# STM32L4R5xx register map
File version: 1.0
Registers are 32-bit, access not given, reset 0x0 unless marked. A register's access mark holds for its fields unless they carry their own. Offsets are from the block's base; [hi:lo] are bit positions; {n}, {i} and the like mark numbered series.

## VREFBUF
Base 0x40010030
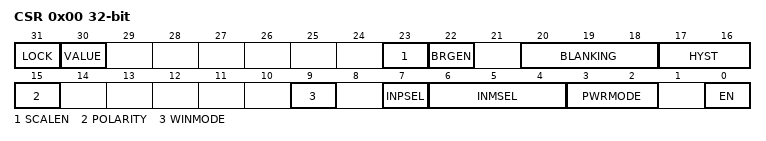
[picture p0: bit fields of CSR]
0x00 CSR
  [3] VRR, [2] VRS, [1] HIZ, [0] ENVR, [5:0] TRIM
0x04 CCR

## COMP1
Base 0x40010200
Same registers: COMP2 0x40010204, COMP12_COMMON 0x40010204
0x00 CSR
  [31] LOCK, [30] VALUE, [23] SCALEN, [22] BRGEN, [20:18] BLANKING, [17:16] HYST, [15] POLARITY, [9] WINMODE, [7] INPSEL, [6:4] INMSEL, [3:2] PWRMODE, [0] EN

## EXTI
Base 0x40010400
0x00 IMR1
  [n] IM{n} (n=0..31), [n] EM{n} (n=0..31), [n] RT{n} (n=18..22), [n] FT{n} (n=18..22), [n] SWI{n} (n=18..22), [n] PIF{n} (n=18..22), [n] RT{n} (n=0..16), [n] FT{n} (n=0..16), [n] SWI{n} (n=0..16), [n] PIF{n} (n=0..16), [8] IM40, [8] EM40, [n-32] IM{n} (n=35..38), [n-32] EM{n} (n=35..38), [n-32] RT{n} (n=35..38), [n-32] FT{n} (n=35..38), [n-32] SWI{n} (n=35..38), [n-32] PIF{n} (n=35..38), [1] IM33, [1] EM33, [0] IM32, [0] EM32
0x04 EMR1
0x08 RTSR1
0x0C FTSR1
0x10 SWIER1
0x14 PR1
0x20 IMR2
0x24 EMR2
0x28 RTSR2
0x2C FTSR2
0x30 SWIER2
0x34 PR2

## FIREWALL
Base 0x40011C00
0x00 CSSA
0x04 CSL
0x08 NVDSSA
0x0C NVDSL
0x10 VDSSA
0x14 VDSL
0x20 CR

## SAI1
Base 0x40015400
Same registers: SAI2 0x40015800
0x00 GCR
  [8n-2:8n-4] DLYM{n}R (n=1..4), [8n-6:8n-8] DLYM{n}L (n=1..4), [n+7] CKEN{n} (n=1..4), [5:4] SYNCOUT, [5:4] MICNBR, [1:0] SYNCIN, [0] PDMEN
0x04 CR1A
0x08 CR2A
0x10 FRCRA
0x1C SLOTRA
0x24 CR1B
0x28 CR2B
0x2C IMRA
0x30 FRCRB
0x3C SLOTRB
0x40 SRA
0x44 PDMCR
0x48 PDMDLY
0x4C IMRB
0x58 CLRFRA
0x60 SRB
0x74 DRA
0x78 CLRFRB
0x94 DRB

## DMA1
Base 0x40020000
Same registers: DMA2 0x40020400
0x00 ISR
  [4n-1] TEIF{n} (n=1..7), [4n-1] CTEIF{n} (n=1..7), [4n-2] HTIF{n} (n=1..7), [4n-2] CHTIF{n} (n=1..7), [4n-3] TCIF{n} (n=1..7), [4n-3] CTCIF{n} (n=1..7), [4n-4] GIF{n} (n=1..7), [4n-4] CGIF{n} (n=1..7), [14] MEM2MEM, [14] MEM2MEM, [14] MEM2MEM, [14] MEM2MEM, [14] MEM2MEM, [14] MEM2MEM, [14] MEM2MEM, [14] MEM2MEM, [14] MEM2MEM, [14] MEM2MEM, [14] MEM2MEM, [14] MEM2MEM, [14] MEM2MEM, [14] MEM2MEM, [13:12] PL, [13:12] PL, [13:12] PL, [13:12] PL, [13:12] PL, [13:12] PL, [13:12] PL, [13:12] PL, [13:12] PL, [13:12] PL, [13:12] PL, [13:12] PL, [13:12] PL, [13:12] PL, [11:10] MSIZE, [11:10] MSIZE, [11:10] MSIZE, [11:10] MSIZE, [11:10] MSIZE, [11:10] MSIZE, [11:10] MSIZE, [11:10] MSIZE, [11:10] MSIZE, [11:10] MSIZE, [11:10] MSIZE, [11:10] MSIZE, [11:10] MSIZE, [11:10] MSIZE, [9:8] PSIZE, [9:8] PSIZE, [9:8] PSIZE, [9:8] PSIZE, [9:8] PSIZE, [9:8] PSIZE, [9:8] PSIZE, [9:8] PSIZE, [9:8] PSIZE, [9:8] PSIZE, [9:8] PSIZE, [9:8] PSIZE, [9:8] PSIZE, [9:8] PSIZE, [7] MINC, [7] MINC, [7] MINC, [7] MINC, [7] MINC, [7] MINC, [7] MINC, [7] MINC, [7] MINC, [7] MINC, [7] MINC, [7] MINC, [7] MINC, [7] MINC, [6] PINC, [6] PINC, [6] PINC, [6] PINC, [6] PINC, [6] PINC, [6] PINC, [6] PINC, [6] PINC, [6] PINC, [6] PINC, [6] PINC, [6] PINC, [6] PINC, [5] CIRC, [5] CIRC, [5] CIRC, [5] CIRC, [5] CIRC, [5] CIRC, [5] CIRC, [5] CIRC, [5] CIRC, [5] CIRC, [5] CIRC, [5] CIRC, [5] CIRC, [5] CIRC, [4] DIR, [4] DIR, [4] DIR, [4] DIR, [4] DIR, [4] DIR, [4] DIR, [4] DIR, [4] DIR, [4] DIR, [4] DIR, [4] DIR, [4] DIR, [4] DIR, [3] TEIE, [3] TEIE, [3] TEIE, [3] TEIE, [3] TEIE, [3] TEIE, [3] TEIE, [3] TEIE, [3] TEIE, [3] TEIE, [3] TEIE, [3] TEIE, [3] TEIE, [3] TEIE, [2] HTIE, [2] HTIE, [2] HTIE, [2] HTIE, [2] HTIE, [2] HTIE, [2] HTIE, [2] HTIE, [2] HTIE, [2] HTIE, [2] HTIE, [2] HTIE, [2] HTIE, [2] HTIE, [1] TCIE, [1] TCIE, [1] TCIE, [1] TCIE, [1] TCIE, [1] TCIE, [1] TCIE, [1] TCIE, [1] TCIE, [1] TCIE, [1] TCIE, [1] TCIE, [1] TCIE, [1] TCIE, [0] EN, [0] EN, [15:0] NDT, [15:0] NDT, [31:0] PA, [31:0] PA, [0] EN, [0] EN, [31:0] MA, [15:0] NDT, [31:0] MA, [15:0] NDT, [31:0] PA, [31:0] PA, [0] EN, [0] EN, [31:0] MA, [15:0] NDT, [31:0] MA, [15:0] NDT, [31:0] PA, [31:0] PA, [0] EN, [0] EN, [31:0] MA, [15:0] NDT, [31:0] MA, [15:0] NDT, [31:0] PA, [31:0] PA, [0] EN, [0] EN, [31:0] MA, [15:0] NDT, [31:0] MA, [15:0] NDT, [31:0] PA, [31:0] PA, [0] EN, [0] EN, [31:0] MA, [15:0] NDT, [31:0] MA, [15:0] NDT, [31:0] PA, [31:0] PA, [0] EN, [0] EN, [31:0] MA, [15:0] NDT, [31:0] MA, [15:0] NDT, [31:0] PA, [31:0] PA, [31:0] MA, [31:0] MA
0x04 IFCR
0x08 CCR1
0x0C CNDTR1
{0x0+0x14*i} CPAR{i} (i=1..7)
0x1C CCR2
{0xC+0x14*i} CMAR{i} (i=1..7)
0x20 CNDTR2
0x30 CCR3
0x34 CNDTR3
0x44 CCR4
0x48 CNDTR4
0x58 CCR5
0x5C CNDTR5
0x6C CCR6
0x70 CNDTR6
0x80 CCR7
0x84 CNDTR7
